# CH32V407 register map
Vendor: WCH Ltd.; File version: 1.0
Registers are 32-bit, read-write, reset 0x0 unless marked. A register's access mark holds for its fields unless they carry their own. Offsets are from the block's base; [hi:lo] are bit positions; {n}, {i} and the like mark numbered series; 'fields as' and 'values as' point back to an identical list.

## DMA1 — DMA1 controller
Base 0x40020000
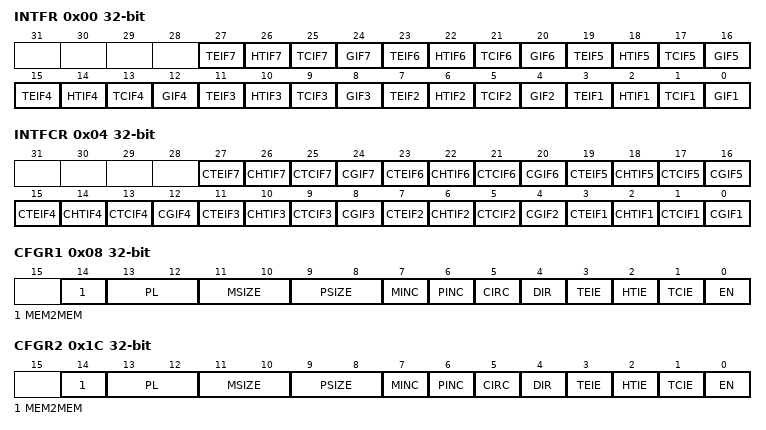
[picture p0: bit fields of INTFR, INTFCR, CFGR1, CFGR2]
0x00 INTFR ro — DMA interrupt status register (DMA_INTFR)
  [4n-1] TEIF{n} (n=1..7) — Channel {n} Transfer Error flag
  [4n-2] HTIF{n} (n=1..7) — Channel {n} Half Transfer Complete flag
  [4n-3] TCIF{n} (n=1..7) — Channel {n} Transfer Complete flag
  [4n-4] GIF{n} (n=1..7) — Channel {n} Global interrupt flag
0x04 INTFCR wo — DMA interrupt flag clear register (DMA_INTFCR)
  [4n-1] CTEIF{n} (n=1..7) — Channel {n} Transfer Error clear
  [4n-2] CHTIF{n} (n=1..7) — Channel {n} Half Transfer clear
  [4n-3] CTCIF{n} (n=1..7) — Channel {n} Transfer Complete clear
  [4n-4] CGIF{n} (n=1..7) — Channel {n} Global interrupt clear
0x08 CFGR1 — DMA channel configuration register (DMA_CFGR)
  [14] MEM2MEM — Memory to memory mode
  [13:12] PL — Channel Priority level
  [11:10] MSIZE — Memory size
  [9:8] PSIZE — Peripheral size
  [7] MINC — Memory increment mode
  [6] PINC — Peripheral increment mode
  [5] CIRC — Circular mode
  [4] DIR — Data transfer direction
  [3] TEIE — Transfer error interrupt enable
  [2] HTIE — Half Transfer interrupt enable
  [1] TCIE — Transfer complete interrupt enable
  [0] EN — Channel enable
0x0C CNTR1 — DMA channel 1 number of data register
  [15:0] NDT — Number of data to transfer
0x10 PADDR1 — DMA channel 1 peripheral address register
  [31:0] PA — Peripheral address
{0x0+0x14*i} MADDR{i} (i=1..7) — DMA channel {i} memory address register
  [31:0] MA — Memory address
0x1C CFGR2 — DMA channel configuration register (DMA_CFGR)
  fields as CFGR1
0x20 CNTR2 — DMA channel 2 number of data register
  [15:0] NDT — Number of data to transfer
0x24 PADDR2 — DMA channel 2 peripheral address register
  [31:0] PA — Peripheral address
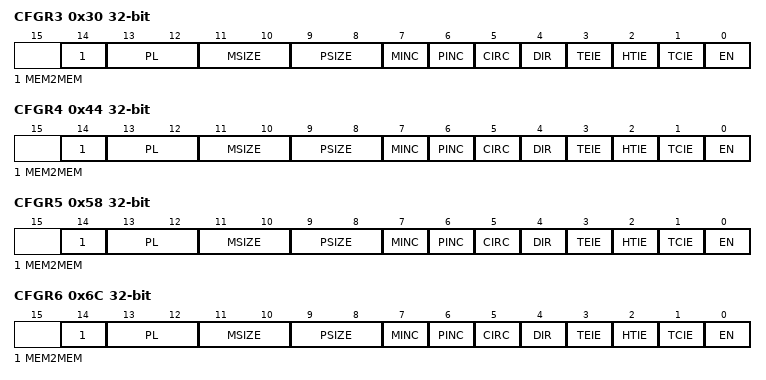
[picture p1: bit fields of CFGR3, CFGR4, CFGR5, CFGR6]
0x30 CFGR3 — DMA channel configuration register (DMA_CFGR)
  fields as CFGR1
0x34 CNTR3 — DMA channel 3 number of data register
  [15:0] NDT — Number of data to transfer
0x38 PADDR3 — DMA channel 3 peripheral address register
  [31:0] PA — Peripheral address
0x44 CFGR4 — DMA channel configuration register (DMA_CFGR)
  fields as CFGR1
0x48 CNTR4 — DMA channel 4 number of data register
  [15:0] NDT — Number of data to transfer
0x4C PADDR4 — DMA channel 4 peripheral address register
  [31:0] PA — Peripheral address
0x58 CFGR5 — DMA channel configuration register (DMA_CFGR)
  fields as CFGR1
0x5C CNTR5 — DMA channel 5 number of data register
  [15:0] NDT — Number of data to transfer
0x60 PADDR5 — DMA channel 5 peripheral address register
  [31:0] PA — Peripheral address
0x6C CFGR6 — DMA channel configuration register (DMA_CFGR)
  fields as CFGR1
0x70 CNTR6 — DMA channel 6 number of data register
  [15:0] NDT — Number of data to transfer
0x74 PADDR6 — DMA channel 6 peripheral address register
  [31:0] PA — Peripheral address
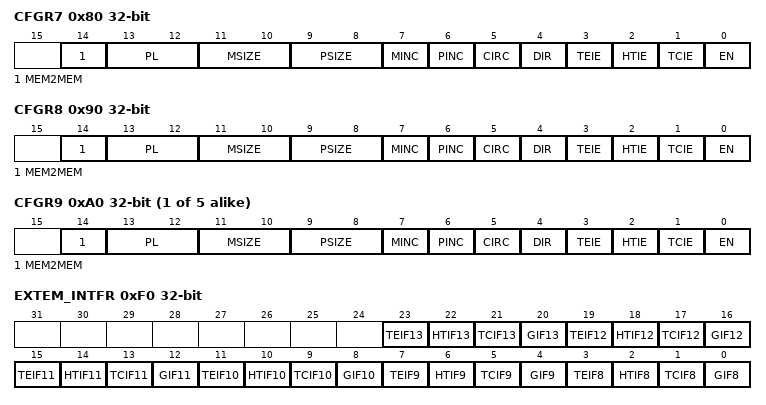
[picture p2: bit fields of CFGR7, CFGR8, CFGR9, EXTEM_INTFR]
0x80 CFGR7 — DMA channel configuration register (DMA_CFGR)
  fields as CFGR1
{0x14+0x10*i} CNTR{i} (i=7..13) — DMA channel {i} number of data register
  [15:0] NDT — Number of data to transfer
{0x18+0x10*i} PADDR{i} (i=7..13) — DMA channel {i} peripheral address register
  [31:0] PA — Peripheral address
0x90 CFGR8 — DMA channel configuration register (DMA_CFGR)
  fields as CFGR1
{0x1C+0x10*i} MADDR{i} (i=8..13) — DMA channel {i} memory address register
  [31:0] MA — Memory address
{0x10+0x10*i} CFGR{i} (i=9..13) — DMA channel {i} configuration register (DMA_CFGR)
  fields as CFGR1
0xF0 EXTEM_INTFR — DMA extends the interrupt status register
  [4n-29] TEIF{n} (n=8..13) — Channel {n} Transfer Error flag
  [4n-30] HTIF{n} (n=8..13) — Channel {n} Half Transfer Complete flag
  [4n-31] TCIF{n} (n=8..13) — Channel {n} Transfer Complete flag
  [4n-32] GIF{n} (n=8..13) — Channel {n} Global interrupt flag
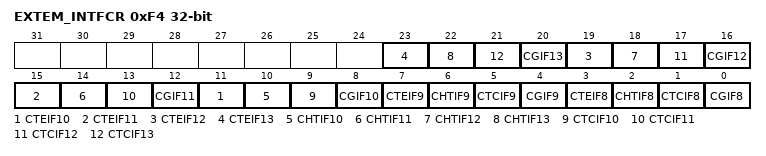
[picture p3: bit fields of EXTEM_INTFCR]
0xF4 EXTEM_INTFCR — DMA extends the interrupt flag clear register
  [4n-29] CTEIF{n} (n=8..13) — Channel {n} Transfer Error clear
  [4n-30] CHTIF{n} (n=8..13) — Channel {n} Half Transfer Complete clear
  [4n-31] CTCIF{n} (n=8..13) — Channel {n} Transfer Complete clear
  [4n-32] CGIF{n} (n=8..13) — Channel {n} Global interrupt clear

## DMA2 — DMA2 controller
Base 0x40020400
Registers as DMA1, without CFGR12, CNTR12, PADDR12, MADDR12, CFGR13, CNTR13, PADDR13, MADDR13, EXTEM_INTFR, EXTEM_INTFCR; these are added or differ:
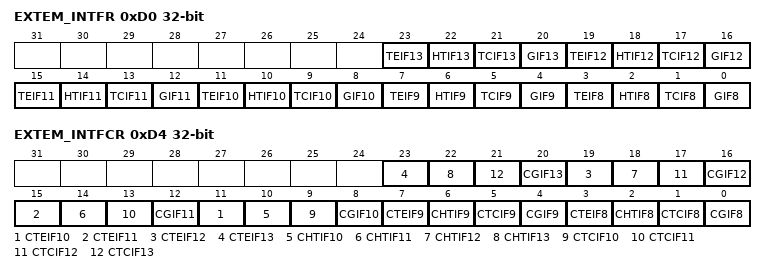
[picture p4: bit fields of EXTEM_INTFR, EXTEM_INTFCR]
0xD0 EXTEM_INTFR — DMA extends the interrupt status register
  fields as DMA1.EXTEM_INTFR
0xD4 EXTEM_INTFCR — DMA extends the interrupt flag clear register
  fields as DMA1.EXTEM_INTFCR
